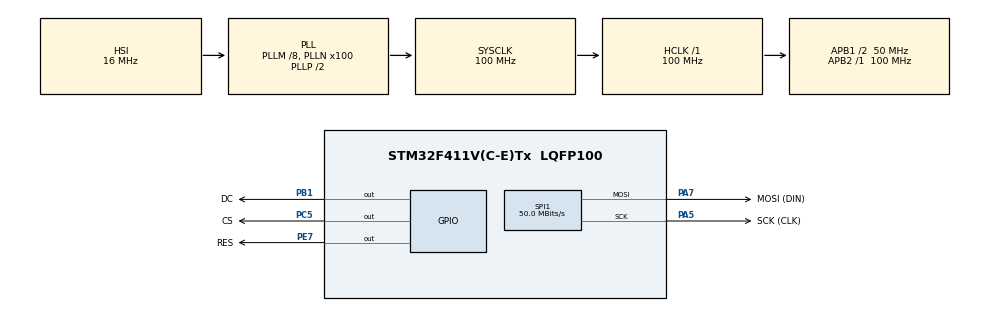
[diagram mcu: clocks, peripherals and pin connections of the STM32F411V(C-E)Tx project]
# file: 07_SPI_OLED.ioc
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Dma.Request0=SPI1_TX
Dma.SPI1_TX.0.Channel=DMA_CHANNEL_2
Dma.SPI1_TX.0.Direction=DMA_MEMORY_TO_PERIPH
Dma.SPI1_TX.0.FIFOMode=DMA_FIFOMODE_DISABLE
Dma.SPI1_TX.0.Instance=DMA2_Stream2
Dma.SPI1_TX.0.MemDataAlignment=DMA_MDATAALIGN_BYTE
Dma.SPI1_TX.0.MemInc=DMA_MINC_ENABLE
Dma.SPI1_TX.0.Mode=DMA_NORMAL
Dma.SPI1_TX.0.PeriphDataAlignment=DMA_PDATAALIGN_BYTE
Dma.SPI1_TX.0.PeriphInc=DMA_PINC_DISABLE
Dma.SPI1_TX.0.Priority=DMA_PRIORITY_LOW
Mcu.Family=STM32F4
Mcu.Name=STM32F411V(C-E)Tx
Mcu.Package=LQFP100
NVIC.DMA2_Stream2_IRQn=true\:0\:0\:false
NVIC.PriorityGroup=NVIC_PRIORITYGROUP_4
NVIC.SPI1_IRQn=true\:0\:0\:false
PA5.GPIO_Label=SCK (CLK)
PA5.Mode=TX_Only_Simplex_Unidirect_Master
PA5.Signal=SPI1_SCK
PA7.GPIO_Label=MOSI (DIN)
PA7.Mode=TX_Only_Simplex_Unidirect_Master
PA7.Signal=SPI1_MOSI
PB1.GPIO_Label=DC
PB1.GPIO_Speed=GPIO_SPEED_HIGH
PB1.Signal=GPIO_Output
PC5.GPIO_Label=CS
PC5.GPIO_Speed=GPIO_SPEED_HIGH
PC5.PinState=GPIO_PIN_RESET
PC5.Signal=GPIO_Output
PE7.GPIO_Label=RES
PE7.GPIO_Speed=GPIO_SPEED_HIGH
PE7.Signal=GPIO_Output
ProjectManager.HeapSize=0x400
ProjectManager.StackSize=0x200
ProjectManager.TargetToolchain=SW4STM32
RCC.48MHZClocksFreq_Value=50000000
RCC.AHBFreq_Value=100000000
RCC.APB1CLKDivider=RCC_HCLK_DIV2
RCC.APB1Freq_Value=50000000
RCC.APB1TimFreq_Value=100000000
RCC.APB2Freq_Value=100000000
RCC.APB2TimFreq_Value=100000000
RCC.CortexFreq_Value=100000000
RCC.HCLKFreq_Value=100000000
RCC.HSE_VALUE=25000000
RCC.HSI_VALUE=16000000
RCC.LSE_VALUE=32768
RCC.PLLM=8
RCC.PLLN=100
RCC.SYSCLKFreq_VALUE=100000000
RCC.SYSCLKSource=RCC_SYSCLKSOURCE_PLLCLK
RCC.VCOOutputFreq_Value=200000000
SPI1.BaudRatePrescaler=SPI_BAUDRATEPRESCALER_2
SPI1.CLKPhase=SPI_PHASE_2EDGE
SPI1.CLKPolarity=SPI_POLARITY_HIGH
SPI1.CalculateBaudRate=50.0 MBits/s
SPI1.Mode=SPI_MODE_MASTER
board=07_SPI_OLED

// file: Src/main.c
/**
 ******************************************************************************
 * File Name          : main.c
 * Description        : Main program body
 ******************************************************************************
 *
 * COPYRIGHT(c) 2016 STMicroelectronics
 *
 * Redistribution and use in source and binary forms, with or without modification,
 * are permitted provided that the following conditions are met:
 *   1. Redistributions of source code must retain the above copyright notice,
 *      this list of conditions and the following disclaimer.
 *   2. Redistributions in binary form must reproduce the above copyright notice,
 *      this list of conditions and the following disclaimer in the documentation
 *      and/or other materials provided with the distribution.
 *   3. Neither the name of STMicroelectronics nor the names of its contributors
 *      may be used to endorse or promote products derived from this software
 *      without specific prior written permission.
 *
 * THIS SOFTWARE IS PROVIDED BY THE COPYRIGHT HOLDERS AND CONTRIBUTORS "AS IS"
 * AND ANY EXPRESS OR IMPLIED WARRANTIES, INCLUDING, BUT NOT LIMITED TO, THE
 * IMPLIED WARRANTIES OF MERCHANTABILITY AND FITNESS FOR A PARTICULAR PURPOSE ARE
 * DISCLAIMED. IN NO EVENT SHALL THE COPYRIGHT HOLDER OR CONTRIBUTORS BE LIABLE
 * FOR ANY DIRECT, INDIRECT, INCIDENTAL, SPECIAL, EXEMPLARY, OR CONSEQUENTIAL
 * DAMAGES (INCLUDING, BUT NOT LIMITED TO, PROCUREMENT OF SUBSTITUTE GOODS OR
 * SERVICES; LOSS OF USE, DATA, OR PROFITS; OR BUSINESS INTERRUPTION) HOWEVER
 * CAUSED AND ON ANY THEORY OF LIABILITY, WHETHER IN CONTRACT, STRICT LIABILITY,
 * OR TORT (INCLUDING NEGLIGENCE OR OTHERWISE) ARISING IN ANY WAY OUT OF THE USE
 * OF THIS SOFTWARE, EVEN IF ADVISED OF THE POSSIBILITY OF SUCH DAMAGE.
 *
 ******************************************************************************
 */
#include "stm32f4xx_hal.h"

/* USER CODE BEGIN Includes */
#include "SSD1331.h"

/* USER CODE END Includes */

SPI_HandleTypeDef hspi1;
DMA_HandleTypeDef hdma_spi1_tx;

/* USER CODE BEGIN PV */
/* Private variables ---------------------------------------------------------*/

/* USER CODE END PV */

void SystemClock_Config(void);
static void MX_GPIO_Init(void);
static void MX_DMA_Init(void);
static void MX_SPI1_Init(void);

/* USER CODE BEGIN PFP */
/* Private function prototypes -----------------------------------------------*/

/* USER CODE END PFP */

int main(void) {

	/* MCU Configuration----------------------------------------------------------*/

	/* Reset of all peripherals, Initializes the Flash interface and the Systick. */
	HAL_Init();

	/* Configure the system clock */
	SystemClock_Config();

	/* Initialize all configured peripherals */
	MX_GPIO_Init();
	MX_DMA_Init();
	MX_SPI1_Init();

	/* USER CODE BEGIN 2 */
	ssd1331_init();
	ssd1331_clear_screen(BLACK);
	ssd1331_display_string(0, 0, "Hello World!", FONT_1608, GREEN);
	/* USER CODE END 2 */

	/* Infinite loop */
	while (1) {

	}

}

/** System Clock Configuration
 */
void SystemClock_Config(void) {

	RCC_OscInitTypeDef RCC_OscInitStruct;
	RCC_ClkInitTypeDef RCC_ClkInitStruct;

	__PWR_CLK_ENABLE()
	;

	__HAL_PWR_VOLTAGESCALING_CONFIG(PWR_REGULATOR_VOLTAGE_SCALE1);

	RCC_OscInitStruct.OscillatorType = RCC_OSCILLATORTYPE_HSI;
	RCC_OscInitStruct.HSIState = RCC_HSI_ON;
	RCC_OscInitStruct.HSICalibrationValue = 16;
	RCC_OscInitStruct.PLL.PLLState = RCC_PLL_ON;
	RCC_OscInitStruct.PLL.PLLSource = RCC_PLLSOURCE_HSI;
	RCC_OscInitStruct.PLL.PLLM = 8;
	RCC_OscInitStruct.PLL.PLLN = 100;
	RCC_OscInitStruct.PLL.PLLP = RCC_PLLP_DIV2;
	RCC_OscInitStruct.PLL.PLLQ = 4;
	HAL_RCC_OscConfig(&RCC_OscInitStruct);

	RCC_ClkInitStruct.ClockType = RCC_CLOCKTYPE_HCLK | RCC_CLOCKTYPE_SYSCLK
			| RCC_CLOCKTYPE_PCLK1 | RCC_CLOCKTYPE_PCLK2;
	RCC_ClkInitStruct.SYSCLKSource = RCC_SYSCLKSOURCE_PLLCLK;
	RCC_ClkInitStruct.AHBCLKDivider = RCC_SYSCLK_DIV1;
	RCC_ClkInitStruct.APB1CLKDivider = RCC_HCLK_DIV2;
	RCC_ClkInitStruct.APB2CLKDivider = RCC_HCLK_DIV1;
	HAL_RCC_ClockConfig(&RCC_ClkInitStruct, FLASH_LATENCY_3);

	HAL_SYSTICK_Config(HAL_RCC_GetHCLKFreq() / 1000);

	HAL_SYSTICK_CLKSourceConfig(SYSTICK_CLKSOURCE_HCLK);

	/* SysTick_IRQn interrupt configuration */
	HAL_NVIC_SetPriority(SysTick_IRQn, 0, 0);
}

/* SPI1 init function */
void MX_SPI1_Init(void) {

	hspi1.Instance = SPI1;
	hspi1.Init.Mode = SPI_MODE_MASTER;
	hspi1.Init.Direction = SPI_DIRECTION_2LINES;
	hspi1.Init.DataSize = SPI_DATASIZE_8BIT;
	hspi1.Init.CLKPolarity = SPI_POLARITY_HIGH;
	hspi1.Init.CLKPhase = SPI_PHASE_2EDGE;
	hspi1.Init.NSS = SPI_NSS_SOFT;
	hspi1.Init.BaudRatePrescaler = SPI_BAUDRATEPRESCALER_2;
	hspi1.Init.FirstBit = SPI_FIRSTBIT_MSB;
	hspi1.Init.TIMode = SPI_TIMODE_DISABLED;
	hspi1.Init.CRCCalculation = SPI_CRCCALCULATION_DISABLED;
	hspi1.Init.CRCPolynomial = 10;
	HAL_SPI_Init(&hspi1);

}

void MX_DMA_Init(void) {
	/* DMA controller clock enable */
	__DMA2_CLK_ENABLE()
	;

	/* DMA interrupt init */
	HAL_NVIC_SetPriority(DMA2_Stream2_IRQn, 0, 0);
	HAL_NVIC_EnableIRQ(DMA2_Stream2_IRQn);

}

/** Configure pins as
 * Analog
 * Input
 * Output
 * EVENT_OUT
 * EXTI
 */
void MX_GPIO_Init(void) {

	GPIO_InitTypeDef GPIO_InitStruct;

	/* GPIO Ports Clock Enable */
	__GPIOA_CLK_ENABLE()
	;
	__GPIOC_CLK_ENABLE()
	;
	__GPIOB_CLK_ENABLE()
	;
	__GPIOE_CLK_ENABLE()
	;

	/*Configure GPIO pin Output Level */
	HAL_GPIO_WritePin(CS_GPIO_Port, CS_Pin, GPIO_PIN_RESET);

	/*Configure GPIO pin Output Level */
	HAL_GPIO_WritePin(DC_GPIO_Port, DC_Pin, GPIO_PIN_RESET);

	/*Configure GPIO pin Output Level */
	HAL_GPIO_WritePin(RES_GPIO_Port, RES_Pin, GPIO_PIN_RESET);

	/*Configure GPIO pin : CS_Pin */
	GPIO_InitStruct.Pin = CS_Pin;
	GPIO_InitStruct.Mode = GPIO_MODE_OUTPUT_PP;
	GPIO_InitStruct.Pull = GPIO_NOPULL;
	GPIO_InitStruct.Speed = GPIO_SPEED_HIGH;
	HAL_GPIO_Init(CS_GPIO_Port, &GPIO_InitStruct);

	/*Configure GPIO pin : DC_Pin */
	GPIO_InitStruct.Pin = DC_Pin;
	GPIO_InitStruct.Mode = GPIO_MODE_OUTPUT_PP;
	GPIO_InitStruct.Pull = GPIO_NOPULL;
	GPIO_InitStruct.Speed = GPIO_SPEED_HIGH;
	HAL_GPIO_Init(DC_GPIO_Port, &GPIO_InitStruct);

	/*Configure GPIO pin : RES_Pin */
	GPIO_InitStruct.Pin = RES_Pin;
	GPIO_InitStruct.Mode = GPIO_MODE_OUTPUT_PP;
	GPIO_InitStruct.Pull = GPIO_NOPULL;
	GPIO_InitStruct.Speed = GPIO_SPEED_HIGH;
	HAL_GPIO_Init(RES_GPIO_Port, &GPIO_InitStruct);

}

/************************ (C) COPYRIGHT STMicroelectronics *****END OF FILE****/
